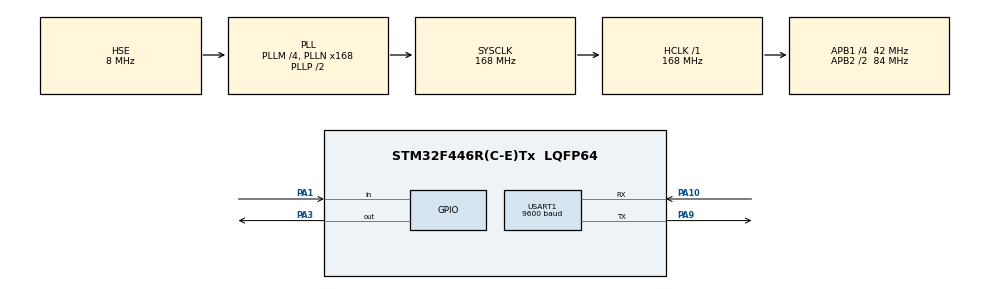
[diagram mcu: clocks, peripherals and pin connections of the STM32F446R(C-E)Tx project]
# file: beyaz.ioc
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Mcu.Family=STM32F4
Mcu.Name=STM32F446R(C-E)Tx
Mcu.Package=LQFP64
NVIC.PriorityGroup=NVIC_PRIORITYGROUP_4
PA1.GPIO_PuPd=GPIO_PULLUP
PA1.Signal=GPIO_Input
PA10.Mode=Asynchronous
PA10.Signal=USART1_RX
PA3.Signal=GPIO_Output
PA9.Mode=Asynchronous
PA9.Signal=USART1_TX
PH0-OSC_IN.Mode=HSE-External-Oscillator
PH0-OSC_IN.Signal=RCC_OSC_IN
PH1-OSC_OUT.Mode=HSE-External-Oscillator
PH1-OSC_OUT.Signal=RCC_OSC_OUT
ProjectManager.HeapSize=0x200
ProjectManager.StackSize=0x400
ProjectManager.TargetToolchain=STM32CubeIDE
RCC.AHBFreq_Value=168000000
RCC.APB1CLKDivider=RCC_HCLK_DIV4
RCC.APB1Freq_Value=42000000
RCC.APB1TimFreq_Value=84000000
RCC.APB2CLKDivider=RCC_HCLK_DIV2
RCC.APB2Freq_Value=84000000
RCC.APB2TimFreq_Value=168000000
RCC.CortexFreq_Value=168000000
RCC.HCLKFreq_Value=168000000
RCC.HSE_VALUE=8000000
RCC.PLLM=4
RCC.PLLN=168
RCC.PLLSourceVirtual=RCC_PLLSOURCE_HSE
RCC.SYSCLKFreq_VALUE=168000000
RCC.SYSCLKSource=RCC_SYSCLKSOURCE_PLLCLK
RCC.USBFreq_Value=168000000
RCC.VCOOutputFreq_Value=336000000
USART1.BaudRate=9600
USART1.VirtualMode=VM_ASYNC
board=custom

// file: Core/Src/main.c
/* USER CODE BEGIN Header */
/**
  ******************************************************************************
  * @file           : main.c
  * @brief          : Main program body
  ******************************************************************************
  * @attention
  *
  * Copyright (c) 2022 STMicroelectronics.
  * All rights reserved.
  *
  * This software is licensed under terms that can be found in the LICENSE file
  * in the root directory of this software component.
  * If no LICENSE file comes with this software, it is provided AS-IS.
  *
  ******************************************************************************
  */
/* USER CODE END Header */
#include "main.h"

 UART_HandleTypeDef huart1;

void SystemClock_Config(void);
static void MX_GPIO_Init(void);
static void MX_USART1_UART_Init(void);

int main(void)
{
  /* USER CODE BEGIN 1 */
HAL_GPIO_WritePin(GPIOA, GPIO_PIN_3, 0);
  /* USER CODE END 1 */

  /* MCU Configuration--------------------------------------------------------*/

  /* Reset of all peripherals, Initializes the Flash interface and the Systick. */
  HAL_Init();

  /* Configure the system clock */
  SystemClock_Config();

  /* Initialize all configured peripherals */
  MX_GPIO_Init();
  MX_USART1_UART_Init();

  /* Infinite loop */
  /* USER CODE BEGIN WHILE */
  while (1)
  {
	  if(HAL_GPIO_ReadPin(GPIOA, GPIO_PIN_1)==0)
	  {

	  HAL_Delay(1000);
	  HAL_GPIO_WritePin(GPIOA, GPIO_PIN_3, 1);
	  HAL_Delay(5);
	  HAL_UART_Transmit(&huart1, "s", 1, 10);
	  HAL_GPIO_WritePin(GPIOA, GPIO_PIN_3, 0);

	  }
    /* USER CODE END WHILE */

  }
}

void SystemClock_Config(void)
{
  RCC_OscInitTypeDef RCC_OscInitStruct = {0};
  RCC_ClkInitTypeDef RCC_ClkInitStruct = {0};

  /** Configure the main internal regulator output voltage
  */
  __HAL_RCC_PWR_CLK_ENABLE();
  __HAL_PWR_VOLTAGESCALING_CONFIG(PWR_REGULATOR_VOLTAGE_SCALE1);

  /** Initializes the RCC Oscillators according to the specified parameters
  * in the RCC_OscInitTypeDef structure.
  */
  RCC_OscInitStruct.OscillatorType = RCC_OSCILLATORTYPE_HSE;
  RCC_OscInitStruct.HSEState = RCC_HSE_ON;
  RCC_OscInitStruct.PLL.PLLState = RCC_PLL_ON;
  RCC_OscInitStruct.PLL.PLLSource = RCC_PLLSOURCE_HSE;
  RCC_OscInitStruct.PLL.PLLM = 4;
  RCC_OscInitStruct.PLL.PLLN = 168;
  RCC_OscInitStruct.PLL.PLLP = RCC_PLLP_DIV2;
  RCC_OscInitStruct.PLL.PLLQ = 2;
  RCC_OscInitStruct.PLL.PLLR = 2;
  if (HAL_RCC_OscConfig(&RCC_OscInitStruct) != HAL_OK)
  {
    Error_Handler();
  }

  /** Initializes the CPU, AHB and APB buses clocks
  */
  RCC_ClkInitStruct.ClockType = RCC_CLOCKTYPE_HCLK|RCC_CLOCKTYPE_SYSCLK
                              |RCC_CLOCKTYPE_PCLK1|RCC_CLOCKTYPE_PCLK2;
  RCC_ClkInitStruct.SYSCLKSource = RCC_SYSCLKSOURCE_PLLCLK;
  RCC_ClkInitStruct.AHBCLKDivider = RCC_SYSCLK_DIV1;
  RCC_ClkInitStruct.APB1CLKDivider = RCC_HCLK_DIV4;
  RCC_ClkInitStruct.APB2CLKDivider = RCC_HCLK_DIV2;

  if (HAL_RCC_ClockConfig(&RCC_ClkInitStruct, FLASH_LATENCY_5) != HAL_OK)
  {
    Error_Handler();
  }
}

static void MX_USART1_UART_Init(void)
{

  huart1.Instance = USART1;
  huart1.Init.BaudRate = 9600;
  huart1.Init.WordLength = UART_WORDLENGTH_8B;
  huart1.Init.StopBits = UART_STOPBITS_1;
  huart1.Init.Parity = UART_PARITY_NONE;
  huart1.Init.Mode = UART_MODE_TX_RX;
  huart1.Init.HwFlowCtl = UART_HWCONTROL_NONE;
  huart1.Init.OverSampling = UART_OVERSAMPLING_16;
  if (HAL_UART_Init(&huart1) != HAL_OK)
  {
    Error_Handler();
  }

}

static void MX_GPIO_Init(void)
{
  GPIO_InitTypeDef GPIO_InitStruct = {0};

  /* GPIO Ports Clock Enable */
  __HAL_RCC_GPIOH_CLK_ENABLE();
  __HAL_RCC_GPIOA_CLK_ENABLE();

  /*Configure GPIO pin Output Level */
  HAL_GPIO_WritePin(GPIOA, GPIO_PIN_3, GPIO_PIN_RESET);

  /*Configure GPIO pin : PA1 */
  GPIO_InitStruct.Pin = GPIO_PIN_1;
  GPIO_InitStruct.Mode = GPIO_MODE_INPUT;
  GPIO_InitStruct.Pull = GPIO_PULLUP;
  HAL_GPIO_Init(GPIOA, &GPIO_InitStruct);

  /*Configure GPIO pin : PA3 */
  GPIO_InitStruct.Pin = GPIO_PIN_3;
  GPIO_InitStruct.Mode = GPIO_MODE_OUTPUT_PP;
  GPIO_InitStruct.Pull = GPIO_NOPULL;
  GPIO_InitStruct.Speed = GPIO_SPEED_FREQ_LOW;
  HAL_GPIO_Init(GPIOA, &GPIO_InitStruct);

}

void Error_Handler(void)
{
  __disable_irq();
  while (1)
  {
  }
}
